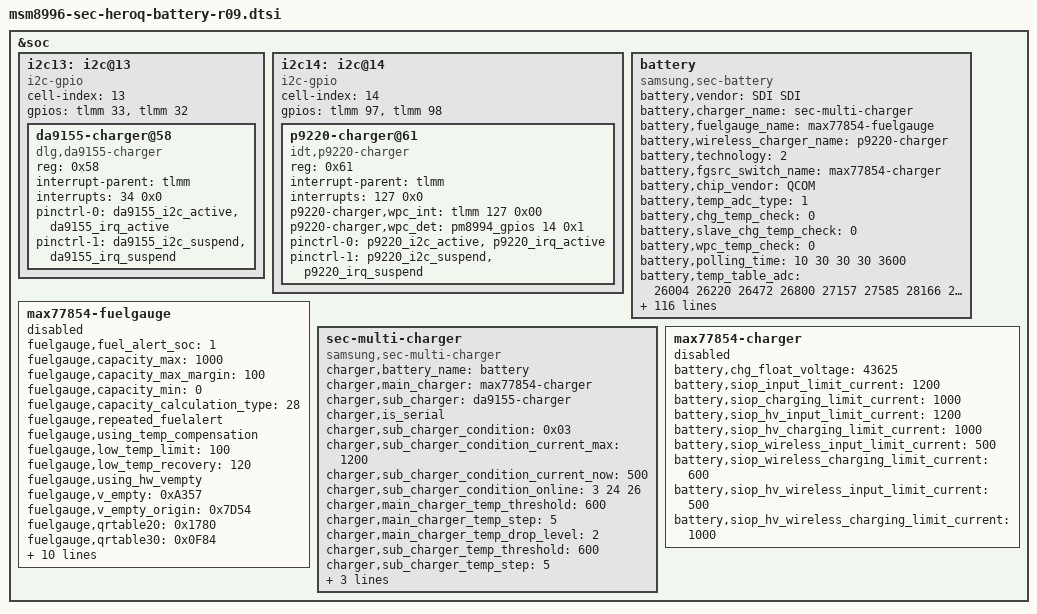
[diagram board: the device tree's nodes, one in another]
/* Copyright (c) 2014, The Linux Foundation. All rights reserved.
 *
 * This program is free software; you can redistribute it and/or modify
 * it under the terms of the GNU General Public License version 2 and
 * only version 2 as published by the Free Software Foundation.
 *
 * This program is distributed in the hope that it will be useful,
 * but WITHOUT ANY WARRANTY; without even the implied warranty of
 * MERCHANTABILITY or FITNESS FOR A PARTICULAR PURPOSE.  See the
 * GNU General Public License for more details.
 */
&soc {
	i2c13: i2c@13 {
		cell-index = <13>;
		compatible = "i2c-gpio";
		gpios = <&tlmm 33 0 /* sda */
			&tlmm 32 0 /* scl */
			>;
		#address-cells = <1>;
		#size-cells = <0>;

		da9155-charger@58 {
			compatible = "dlg,da9155-charger";
			reg = <0x58>;
			interrupt-parent = <&tlmm>;
			interrupts = <34 0x0>;
			/*da9155-charger,irq-gpio = <&tlmm 34 0x00>;*/
			pinctrl-names = "da9155_active", "da9155_suspend";
			pinctrl-0 = <&da9155_i2c_active &da9155_irq_active>;
			pinctrl-1 = <&da9155_i2c_suspend &da9155_irq_suspend>;
		};
	};

	i2c14: i2c@14 {
		cell-index = <14>;
		compatible = "i2c-gpio";
		gpios = <&tlmm 97 0 /* sda */
			&tlmm 98 0 /* scl */
			>;
		#address-cells = <1>;
		#size-cells = <0>;

		p9220-charger@61 {
			compatible = "idt,p9220-charger";
			reg = <0x61>;
			interrupt-parent = <&tlmm>;
			interrupts = <127 0x0>;
			p9220-charger,wpc_int = <&tlmm 127 0x00>;
			p9220-charger,wpc_det = <&pm8994_gpios 14 0x1>;
			pinctrl-names = "p9220_active", "p9220_suspend";
			pinctrl-0 = <&p9220_i2c_active &p9220_irq_active>;
			pinctrl-1 = <&p9220_i2c_suspend &p9220_irq_suspend>;
		};
	};

	battery {
		status = "okay";
		compatible = "samsung,sec-battery";
		battery,vendor = "SDI SDI";
		battery,charger_name = "sec-multi-charger";
		battery,fuelgauge_name = "max77854-fuelgauge";
		battery,wireless_charger_name = "p9220-charger";
		battery,technology = <2>; /* POWER_SUPPLY_TECHNOLOGY_LION */
		battery,fgsrc_switch_name = "max77854-charger"; /* Fuelgauge voltage source */

		battery,chip_vendor = "QCOM";
		battery,temp_adc_type = <1>; /* SEC_BATTERY_ADC_TYPE_AP */

		battery,chg_temp_check = <0>;
		battery,slave_chg_temp_check = <0>;
		battery,wpc_temp_check = <0>;

		battery,polling_time = <10 30 30 30 3600>;

		battery,temp_table_adc = <26004 26220 26472 26800 27157 27585 28166 28667 29327 30063
					  30895 31872 32845 33835 34859 35777 36877 37857 38794 39699
					  40403 40994 41482>;
		battery,temp_table_data = <900 850 800 750 700 650 600 550 500 450
					   400 350 300 250 200 150 100 50 0 (-50)
					   (-100) (-150) (-200)>;

		battery,chg_temp_table_adc = <26004 26220 26472 26800 27157 27585 28166 28667 29327 30063
					  30895 31872 32845 33835 34859 35777 36877 37857 38794 39699
					  40403 40994 41482>;
		battery,chg_temp_table_data = <900 850 800 750 700 650 600 550 500 450
					   400 350 300 250 200 150 100 50 0 (-50)
					   (-100) (-150) (-200)>;

		battery,wpc_temp_table_adc = <26004 26220 26472 26800 27157 27585 28166 28667 29327 30063
					  30895 31872 32845 33835 34859 35777 36877 37857 38794 39699
					  40403 40994 41482>;
		battery,wpc_temp_table_data =<900 850 800 750 700 650 600 550 500 450
					   400 350 300 250 200 150 100 50 0 (-50)
					   (-100) (-150) (-200)>;

		battery,input_current_limit = <1800 500 500 1800 500 900 1000 500 1000 500 900 1900 1800 500 500 400 700 1300 300 1000 1500 500 1667 1000 1667 80 1800 1667 1400 1000 1000 500 1000 900>;
		battery,fast_charging_current = <2100 0 0 2100 500 1200 1000 500 1200 0 1400 1600 2100 0 0 400 700 1300 300 1000 1500 0 3000 1000 3000 80 1800 1000 1400 0 1000 500 2100 1400>;
		battery,full_check_current_1st = <350 0 0 350 350 350 350 350 350 0 350 350 350 350 350 0 0 350 350 350 350 350 350 0 350 350 350 0 350 350 350 0 350 350>;
		battery,full_check_current_2nd = <150 0 0 150 150 150 150 150 150 0 150 150 150 150 150 0 0 150 150 150 150 150 150 0 150 150 150 0 150 150 150 0 150 150>;

		battery,wireless_cc_cv = <95>;
		battery,fod_data = <122 30 168 30 168 30 168 30 170 30 178 20>;
		battery,wpc_cv_call_vout = <5600>;
		battery,wpc_cc_call_vout = <5600>;
		battery,wpc_det = <&pm8994_gpios 14 0x1>;

		battery,adc_check_count = <5>;

		battery,cable_check_type = <4>; /* SEC_BATTERY_CABLE_CHECK_PSY */
		battery,cable_source_type = <1>; /* SEC_BATTERY_CABLE_SOURCE_EXTERNAL */
		battery,polling_type = <1>; /* SEC_BATTERY_MONITOR_ALARM */
		battery,monitor_initial_count = <3>;

		battery,battery_check_type = <0>; /* SEC_BATTERY_CHECK_NONE */
		battery,check_count = <0>;
		battery,check_adc_max = <1440>;
		battery,check_adc_min = <0>;

		battery,ovp_uvlo_check_type = <3>; /* SEC_BATTERY_OVP_UVLO_CHGPOLLING */

		battery,thermal_source = <2>; /* SEC_BATTERY_THERMAL_SOURCE_ADC */

		battery,temp_check_type = <0>; /* SEC_BATTERY_TEMP_CHECK_NONE */
		battery,temp_check_count = <1>;
		battery,temp_highlimit_threshold_event = <800>;
		battery,temp_highlimit_recovery_event = <750>;
		battery,temp_high_threshold_event = <600>;
		battery,temp_high_recovery_event = <450>;
		battery,temp_low_threshold_event = <(-50)>;
		battery,temp_low_recovery_event = <0>;
		battery,temp_highlimit_threshold_normal = <800>;
		battery,temp_highlimit_recovery_normal = <750>;
		battery,temp_high_threshold_normal = <600>;
		battery,temp_high_recovery_normal = <450>;
		battery,temp_low_threshold_normal = <(-50)>;
		battery,temp_low_recovery_normal = <0>;
		battery,temp_highlimit_threshold_lpm = <800>;
		battery,temp_highlimit_recovery_lpm = <750>;
		battery,temp_high_threshold_lpm = <600>;
		battery,temp_high_recovery_lpm = <450>;
		battery,temp_low_threshold_lpm = <(-50)>;
		battery,temp_low_recovery_lpm = <0>;
		battery,full_check_type = <7>; /* SEC_BATTERY_FULLCHARGED_CHGPSY */
		battery,full_check_type_2nd = <7>; /* SEC_BATTERY_FULLCHARGED_CHGPSY */
		battery,full_check_count = <1>;
		battery,chg_gpio_full_check = <0>;
		battery,chg_polarity_full_check = <1>;

		battery,chg_high_temp_1st = <500>;
		battery,chg_high_temp_2nd = <500>;
		battery,chg_high_temp_recovery = <490>;
		battery,chg_charging_limit_current = <1400>;
		battery,chg_charging_limit_current_2nd = <1400>;
		battery,chg_skip_check_capacity = <10>;
		battery,chg_skip_check_time = <600>;

		battery,wpc_high_temp = <390>;
		battery,wpc_high_temp_recovery = <385>;
		battery,wpc_lcd_on_high_temp = <380>;
		battery,wpc_lcd_on_high_temp_rec = <370>;
		battery,wpc_charging_limit_current = <700>;
		battery,wpc_skip_check_capacity = <10>;
		battery,wpc_skip_check_time = <600>;

		battery,sleep_mode_limit_current = <500>;

		/* SEC_BATTERY_FULL_CONDITION_SOC |
		   SEC_BATTERY_FULL_CONDITION_NOTIMEFULL |
		   SEC_BATTERY_FULL_CONDITION_VCELL */
		battery,full_condition_type = <13>;
		battery,full_condition_soc = <93>;
		battery,full_condition_vcell = <4300>;

		battery,recharge_check_count = <1>;
		battery,recharge_condition_type = <4>; /* SEC_BATTERY_RECHARGE_CONDITION_VCELL */
		battery,recharge_condition_soc = <98>;
		battery,recharge_condition_vcell = <4310>;

		battery,charging_total_time = <21600>;
		battery,recharging_total_time = <5400>;
		battery,charging_reset_time = <0>;
		qcom,sec-battery-vadc = <&pm8994_vadc>;

		battery,chg_float_voltage = <43625>;

		battery,swelling_high_temp_block = <450>;
		battery,swelling_high_temp_recov = <400>;
		battery,swelling_low_temp_block = <100>;
		battery,swelling_low_temp_recov = <150>;
		
		battery,swelling_low_temp_current = <1500>;	/* 0.5C */
		battery,swelling_low_temp_topoff = <150>;	/* 0.05C */
		battery,swelling_high_temp_current = <2100>;	/* 0.7C */
		battery,swelling_high_temp_topoff = <150>;	/* 0.05C */
		
		battery,swelling_drop_float_voltage = <42000>;
		battery,swelling_high_rechg_voltage = <4150>;
		battery,swelling_low_rechg_voltage = <4050>;

		battery,self_discharging_temp_block = <600>;
		battery,self_discharging_volt_block = <4250>;
		battery,self_discharging_temp_recov = <550>;
		battery,self_discharging_temp_pollingtime = <400>;

		battery,siop_event_check_type = <0>;
		battery,siop_call_cv_current = <600>;
		battery,siop_call_cc_current = <600>;

		battery,siop_input_limit_current = <1200>;
		battery,siop_charging_limit_current = <1000>;
		battery,siop_hv_input_limit_current = <700>;
		battery,siop_hv_charging_limit_current = <1000>;

		battery,siop_wireless_input_limit_current = <500>;
		battery,siop_wireless_charging_limit_current = <600>;
		battery,siop_hv_wireless_input_limit_current = <500>;
		battery,siop_hv_wireless_charging_limit_current = <1000>;
	};

	max77854-fuelgauge {
		status = "disable";
		fuelgauge,fuel_alert_soc = <1>;
		fuelgauge,capacity_max = <1000>;
		fuelgauge,capacity_max_margin = <100>;
		fuelgauge,capacity_min = <0>;
		fuelgauge,capacity_calculation_type = <28>;
		fuelgauge,repeated_fuelalert;
		fuelgauge,using_temp_compensation;
		fuelgauge,low_temp_limit = <100>;
		fuelgauge,low_temp_recovery = <120>;
		fuelgauge,using_hw_vempty;
		fuelgauge,v_empty = <0xA357>; /* Empty: 3260mV, Recover: 3480mV */
		fuelgauge,v_empty_origin = <0x7D54>; /* Empty: 2500mV , Recover: 3360mV */
		fuelgauge,qrtable20 = <0x1780>;
		fuelgauge,qrtable30 = <0x0F84>;
		fuelgauge,fg_resistor = <2>;
		fuelgauge,rcomp0 = <0x3C>;
		fuelgauge,rcomp_charging = <0x3C>;
		fuelgauge,is_using_model_data;
		fuelgauge,type_str = "SDI";
		fuelgauge,capacity = <0x14C2>;
		/*fuelgauge,auto_discharge_en;*/
		fuelgauge,discharge_temp_threshold = <600>;
		fuelgauge,discharge_volt_threshold = <4200>;
		fuelgauge,cv_data = <2565  680    2580
			2483  688    2549
			2405  696    2519
			2333  704    2489
			2263  711    2458
			2196  718    2428
			2137  725    2398
			2077  732    2367
			2016  738    2337
			1964  745    2306
			1894  751    2276
			1835  757    2246
			1783  763    2215
			1727  769    2185
			1674  774    2155
			1621  780    2124
			1571  785    2094
			1525  790    2064
			1480  795    2033
			1437  800    2003
			1391  804    1973
			1353  809    1942
			1311  814    1912
			1272  818    1882
			1235  822    1851
			1198  826    1821
			1161  830    1791
			1124  834    1760
			1092  838    1730
			1059  841    1700
			1027  845    1669
			996   848    1639
			969   852    1608
			940   855    1578
			909   858    1548
			885   861    1517
			863   864    1487
			840   867    1457
			817   870    1426
			794   872    1396
			771   875    1366
			749   878    1335
			725   880    1305
			707   883    1275
			696   885    1244
			674   887    1214
			658   890    1184
			640   892    1153
			618   894    1123
			608   896    1093
			604   898    1062
			584   900    1032
			567   903    1002
			553   909    971
			539   913    941
			524   918    910
			515   921    880
			507   924    850
			494   929    820
			476   934    789
			469   937    759
			459   939    729
			449   943    698
			438   946    668
			431   949    638
			419   952    607
			408   957    577
			402   958    546
			389   962    516
			385   964    486
			377   966    455
			371   968    425
			359   972    395
			353   975    364
			347   976    334
			337   979    304
			331   981    273
			327   983    243
			323   985    213
			319   986    182
			306   989    152
			303   992    122
			298   993    91
			293   996    61
			290   997    31
			0     1000   0 >;
	};

	sec-multi-charger {
		status = "ok";
		compatible = "samsung,sec-multi-charger";

		charger,battery_name = "battery";
		charger,main_charger = "max77854-charger";
		charger,sub_charger = "da9155-charger";

		charger,is_serial;

		charger,sub_charger_condition = <0x03>;
		charger,sub_charger_condition_current_max = <1200>;
		charger,sub_charger_condition_current_now = <500>;
		charger,sub_charger_condition_online = <3 24 26>;

		charger,main_charger_temp_threshold = <600>;
		charger,main_charger_temp_step = <5>;
		charger,main_charger_temp_drop_level = <2>;

		charger,sub_charger_temp_threshold = <600>;
		charger,sub_charger_temp_step = <5>;
		charger,sub_charger_temp_drop_level = <2>;

		charger,main_charger_current_level = <100>;
		charger,sub_charger_current_level = <100>;
	};

	max77854-charger {
	    status = "disable";
		battery,chg_float_voltage = <43625>;

		battery,siop_input_limit_current = <1200>;
		battery,siop_charging_limit_current = <1000>;
		battery,siop_hv_input_limit_current = <1200>;
		battery,siop_hv_charging_limit_current = <1000>;

		battery,siop_wireless_input_limit_current = <500>;
		battery,siop_wireless_charging_limit_current = <600>;
		battery,siop_hv_wireless_input_limit_current = <500>;
		battery,siop_hv_wireless_charging_limit_current = <1000>;
	};
};
